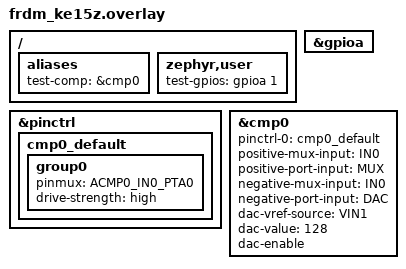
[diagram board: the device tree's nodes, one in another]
/*
 * Copyright (c) 2024 Nordic Semiconductor
 * Copyright 2026 NXP
 *
 * SPDX-License-Identifier: Apache-2.0
 */

#include <nxp/kinetis/MKE15Z256VLL7-pinctrl.h>
#include <zephyr/dt-bindings/gpio/gpio.h>

/*
 * PTA1 looped back to PTA0 (Arduino J4-4 to J4-2 on FRDM-KE15Z).
 */

/ {
	aliases {
		test-comp = &cmp0;
	};

	zephyr,user {
		test-gpios = <&gpioa 1 GPIO_ACTIVE_HIGH>;
	};
};

&gpioa {
	status = "okay";
};

&pinctrl {
	cmp0_default: cmp0_default {
		group0 {
			pinmux = <ACMP0_IN0_PTA0>;
			drive-strength = "high";
		};
	};
};

&cmp0 {
	pinctrl-0 = <&cmp0_default>;
	pinctrl-names = "default";
	status = "okay";

	positive-mux-input = "IN0";
	positive-port-input = "MUX";
	negative-mux-input = "IN0";
	negative-port-input = "DAC";

	dac-vref-source = "VIN1";
	dac-value = <128>;
	dac-enable;
};
